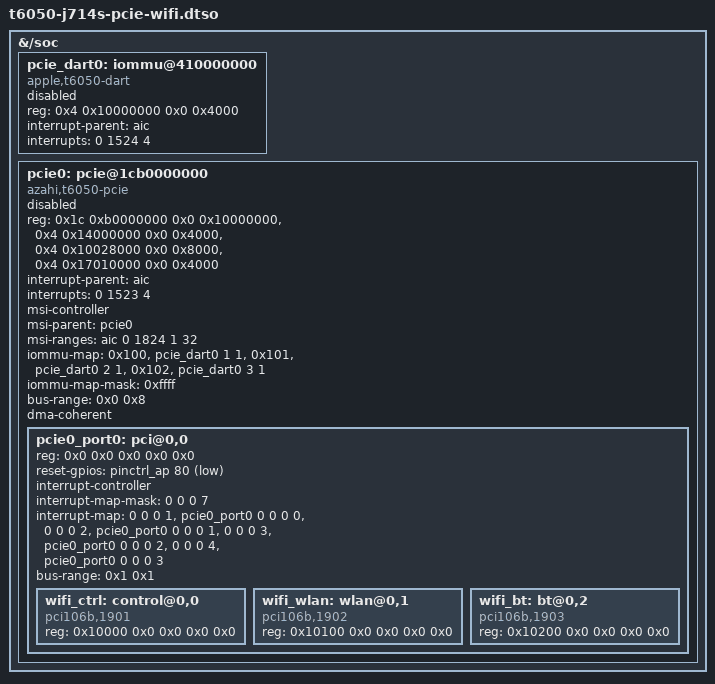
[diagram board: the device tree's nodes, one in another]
// SPDX-License-Identifier: GPL-2.0
/*
 * J714s Apple N1 (Centauri) Wi-Fi PCIe overlay, port 0 only.
 *
 * GENERATED by pcie-driver/gen-pcie-dt.py from the macOS restore-image ADT.
 * Do not edit by hand; regenerate from the ADT and re-run test-pcie-dt.py.
 *
 * Merge onto a base DTB with fdtoverlay at build time, then boot. Base
 * references (aic, pinctrl_ap) use labels, so build the base with dtc -@.
 * The apcie0 controller must already be brought up by the loader
 * (standalone-loader/.../azahi_pcie.c) and its GP power domains left on;
 * this overlay only describes the hardware so pcie-apple can train port 0
 * and a PCI driver can bind 106b:1901/1902/1903. No power-domains here: the
 * loader prepares power, exactly like the USB overlay (pd_ignore_unused).
 *
 * The sd-reader port (pci-bridge1) is intentionally omitted.
 */
/dts-v1/;
/plugin/;

&{/soc} {
	pcie_dart0: iommu@410000000 {
		compatible = "apple,t6050-dart", "apple,t8110-dart";
		status = "disabled";  /* azahi_pcie.c enables after bring-up */
		reg = <0x4 0x10000000 0x0 0x4000>;
		interrupt-parent = <&aic>;
		interrupts = <0 1524 4>;
		#iommu-cells = <1>;
	};

	pcie0: pcie@1cb0000000 {
		compatible = "azahi,t6050-pcie";
		status = "disabled";  /* azahi_pcie.c enables after bring-up */
		device_type = "pci";
		reg = <0x1c 0xb0000000 0x0 0x10000000>,
		      <0x4 0x14000000 0x0 0x4000>,
		      <0x4 0x10028000 0x0 0x8000>,
		      <0x4 0x17010000 0x0 0x4000>;
		reg-names = "config", "rc", "port0", "phy0";
		interrupt-parent = <&aic>;
		interrupts = <0 1523 4>;
		msi-controller;
		msi-parent = <&pcie0>;
		msi-ranges = <&aic 0 1824 1 32>;
		iommu-map = <0x100 &pcie_dart0 1 1>,
			    <0x101 &pcie_dart0 2 1>,
			    <0x102 &pcie_dart0 3 1>;
		iommu-map-mask = <0xffff>;
		bus-range = <0x0 0x8>;
		#address-cells = <3>;
		#size-cells = <2>;
		ranges = <0x43000000 0xb 0xc0000000 0xb 0xc0000000 0x0 0x20000000>,
					 <0x02000000 0x0 0x80000000 0xb 0x80000000 0x0 0x40000000>;
		dma-coherent;

		pcie0_port0: pci@0,0 {
			device_type = "pci";
			reg = <0x0 0x0 0x0 0x0 0x0>;
			/* function-perst GPIO 80 on pinctrl_ap (gpio0/AP), active low */
			reset-gpios = <&pinctrl_ap 80 1>;
			#address-cells = <3>;
			#size-cells = <2>;
			ranges;
			interrupt-controller;
			#interrupt-cells = <1>;
			interrupt-map-mask = <0 0 0 7>;
			interrupt-map = <0 0 0 1 &pcie0_port0 0 0 0 0>,
					<0 0 0 2 &pcie0_port0 0 0 0 1>,
					<0 0 0 3 &pcie0_port0 0 0 0 2>,
					<0 0 0 4 &pcie0_port0 0 0 0 3>;
			bus-range = <0x1 0x1>;

			wifi_ctrl: control@0,0 {
				compatible = "pci106b,1901";
				reg = <0x10000 0x0 0x0 0x0 0x0>;
			};

			wifi_wlan: wlan@0,1 {
				compatible = "pci106b,1902";
				reg = <0x10100 0x0 0x0 0x0 0x0>;
			};

			wifi_bt: bt@0,2 {
				compatible = "pci106b,1903";
				reg = <0x10200 0x0 0x0 0x0 0x0>;
			};
		};
	};
};
